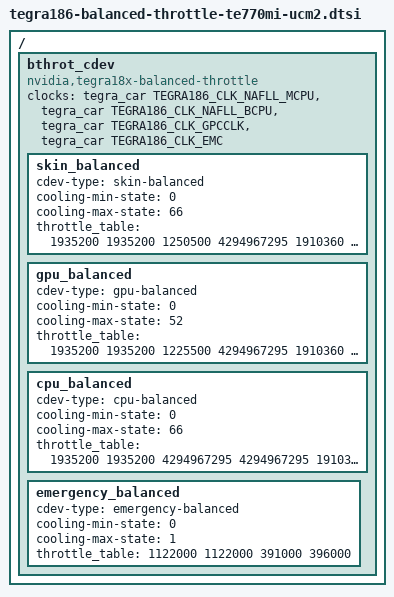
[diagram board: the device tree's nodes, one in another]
/*
 * arch/arm64/boot/dts/tegra186-platforms/tegra186-balanced-throttle-te770mi-ucm2.dtsi
 *
 * Copyright (c) 2015-2017, NVIDIA CORPORATION.  All rights reserved.
 *
 * This program is free software; you can redistribute it and/or modify
 * it under the terms of the GNU General Public License as published by
 * the Free Software Foundation; version 2 of the License.
 *
 * This program is distributed in the hope that it will be useful, but WITHOUT
 * ANY WARRANTY; without even the implied warranty of MERCHANTABILITY or
 * FITNESS FOR A PARTICULAR PURPOSE.  See the GNU General Public License for
 * more details.
 *
 * You should have received a copy of the GNU General Public License along
 * with this program; if not, write to the Free Software Foundation, Inc.,
 * 51 Franklin Street, Fifth Floor, Boston, MA  02110-1301, USA.
 *
 */

/{
	bthrot_cdev {
		compatible = "nvidia,tegra18x-balanced-throttle";
		clocks = <&tegra_car TEGRA186_CLK_NAFLL_MCPU>,
				 <&tegra_car TEGRA186_CLK_NAFLL_BCPU>,
				 <&tegra_car TEGRA186_CLK_GPCCLK>,
				 <&tegra_car TEGRA186_CLK_EMC>;
		clock-names = "mcpu", "bcpu", "gpu", "emc";

		skin_balanced {
			cdev-type = "skin-balanced";
			cooling-min-state = <0>;
			cooling-max-state = <66>;
			#cooling-cells = <2>;
			throttle_table = <
				1935200	1935200	1250500	4294967295
				1910360	1910360	1232796	4294967295
				1885520	1885520	1215092	4294967295
				1860680	1860680	1197388	4294967295
				1835840	1835840	1179685	4294967295
				1811000	1811000	1161981	4294967295
				1786160	1786160	1144277	4294967295
				1761320	1761320	1126573	4294967295
				1736480	1736480	1108869	4294967295
				1711640	1711640	1091165	4294967295
				1686800	1686800	1073462	4294967295
				1661960	1661960	1055758	4294967295
				1637120	1637120	1038054	4294967295
				1612280	1612280	1020350	4294967295
				1587440	1587440	1002646	4294967295
				1562600	1562600	984942	4294967295
				1537760	1537760	967238	4294967295
				1512920	1512920	949535	4294967295
				1488080	1488080	931831	4294967295
				1463240	1463240	914127	4294967295
				1438400	1438400	896423	4294967295
				1413560	1413560	878719	4294967295
				1388720	1388720	861015	4294967295
				1363880	1363880	843312	4294967295
				1339040	1339040	825608	4294967295
				1314200	1314200	807904	4294967295
				1289360	1289360	790200	4294967295
				1264520	1264520	772496	4294967295
				1239680	1239680	754792	4294967295
				1214840	1214840	737088	4294967295
				1190000	1190000	719385	4294967295
				1165160	1165160	701681	4294967295
				1140320	1140320	683977	4294967295
				1115480	1115480	666273	4294967295
				1090640	1090640	648569	4294967295
				1065800	1065800	630865	4294967295
				1040960	1040960	613162	4294967295
				1016120	1016120	595458	4294967295
				991280	991280	577754	4294967295
				966440	966440	560050	4294967295
				941600	941600	542346	4294967295
				916760	916760	524642	4294967295
				891920	891920	506938	4294967295
				867080	867080	489235	4294967295
				842240	842240	471531	4294967295
				817400	817400	453827	4294967295
				792560	792560	436123	4294967295
				767720	767720	418419	4294967295
				742880	742880	400715	4294967295
				718040	718040	383012	4294967295
				693200	693200	365308	4294967295
				668360	668360	347604	4294967295
				643520	643520	329900	4294967295
				618680	618680	312196	4294967295
				593840	593840	294492	4294967295
				569000	569000	276788	4294967295
				544160	544160	259085	4294967295
				519320	519320	241381	4294967295
				494480	494480	223677	4294967295
				469640	469640	205973	4294967295
				444800	444800	188269	4294967295
				419960	419960	170565	4294967295
				395120	395120	152862	4294967295
				370280	370280	135158	4294967295
				345440	345440	117454	4294967295
				320600	320600	99750	4294967295
			>;
		};
		gpu_balanced {
			cdev-type = "gpu-balanced";
			cooling-min-state = <0>;
			cooling-max-state = <52>;
			#cooling-cells = <2>;
			throttle_table = <
				1935200	1935200	1225500	4294967295
				1910360	1910360	1203426	4294967295
				1885520	1885520	1181353	4294967295
				1860680	1860680	1159279	4294967295
				1835840	1835840	1137206	4294967295
				1811000	1811000	1115132	4294967295
				1786160	1786160	1093059	4294967295
				1761320	1761320	1070985	4294967295
				1736480	1736480	1048912	4294967295
				1711640	1711640	1026838	4294967295
				1686800	1686800	1004765	4294967295
				1661960	1661960	982691	4294967295
				1637120	1637120	960618	4294967295
				1612280	1612280	938544	4294967295
				1587440	1587440	916471	4294967295
				1562600	1562600	894397	4294967295
				1537760	1537760	872324	4294967295
				1512920	1512920	850250	4294967295
				1488080	1488080	828176	4294967295
				1463240	1463240	806103	4294967295
				1438400	1438400	784029	4294967295
				1413560	1413560	761956	4294967295
				1388720	1388720	739882	4294967295
				1363880	1363880	717809	4294967295
				1339040	1339040	695735	4294967295
				1314200	1314200	673662	4294967295
				1289360	1289360	651588	4294967295
				1264520	1264520	629515	4294967295
				1239680	1239680	607441	4294967295
				1214840	1214840	585368	4294967295
				1190000	1190000	563294	4294967295
				1165160	1165160	541221	4294967295
				1140320	1140320	519147	4294967295
				1115480	1115480	497074	4294967295
				1090640	1090640	475000	4294967295
				1065800	1065800	452926	4294967295
				1040960	1040960	430853	4294967295
				1016120	1016120	408779	4294967295
				991280	991280	386706	4294967295
				966440	966440	364632	4294967295
				941600	941600	342559	4294967295
				916760	916760	320485	4294967295
				891920	891920	298412	4294967295
				867080	867080	276338	4294967295
				842240	842240	254265	4294967295
				817400	817400	232191	4294967295
				792560	792560	210118	4294967295
				767720	767720	188044	4294967295
				742880	742880	165971	4294967295
				718040	718040	143897	4294967295
				693200	693200	121824	4294967295
				668360	668360	99750	4294967295
			>;
		};
		cpu_balanced {
			cdev-type = "cpu-balanced";
			cooling-min-state = <0>;
			cooling-max-state = <66>;
			#cooling-cells = <2>;
			throttle_table = <
				1935200	1935200	4294967295	4294967295
				1910360	1910360	4294967295	4294967295
				1885520	1885520	4294967295	4294967295
				1860680	1860680	4294967295	4294967295
				1835840	1835840	4294967295	4294967295
				1811000	1811000	4294967295	4294967295
				1786160	1786160	4294967295	4294967295
				1761320	1761320	4294967295	4294967295
				1736480	1736480	4294967295	4294967295
				1711640	1711640	4294967295	4294967295
				1686800	1686800	1300500	4294967295
				1661960	1661960	1278668	4294967295
				1637120	1637120	1256836	4294967295
				1612280	1612280	1235005	4294967295
				1587440	1587440	1213173	4294967295
				1562600	1562600	1191341	4294967295
				1537760	1537760	1169509	4294967295
				1512920	1512920	1147677	4294967295
				1488080	1488080	1125845	4294967295
				1463240	1463240	1104014	4294967295
				1438400	1438400	1082182	4294967295
				1413560	1413560	1060350	4294967295
				1388720	1388720	1038518	4294967295
				1363880	1363880	1016686	4294967295
				1339040	1339040	994855	4294967295
				1314200	1314200	973023	4294967295
				1289360	1289360	951191	4294967295
				1264520	1264520	929359	4294967295
				1239680	1239680	907527	4294967295
				1214840	1214840	885695	4294967295
				1190000	1190000	863864	4294967295
				1165160	1165160	842032	4294967295
				1140320	1140320	820200	4294967295
				1115480	1115480	798368	4294967295
				1090640	1090640	776536	4294967295
				1065800	1065800	754705	4294967295
				1040960	1040960	732873	4294967295
				1016120	1016120	711041	4294967295
				991280	991280	689209	4294967295
				966440	966440	667377	4294967295
				941600	941600	645545	4294967295
				916760	916760	623714	4294967295
				891920	891920	601882	4294967295
				867080	867080	580050	4294967295
				842240	842240	558218	4294967295
				817400	817400	536386	4294967295
				792560	792560	514555	4294967295
				767720	767720	492723	4294967295
				742880	742880	470891	4294967295
				718040	718040	449059	4294967295
				693200	693200	427227	4294967295
				668360	668360	405395	4294967295
				643520	643520	383564	4294967295
				618680	618680	361732	4294967295
				593840	593840	339900	4294967295
				569000	569000	318068	4294967295
				544160	544160	296236	4294967295
				519320	519320	274405	4294967295
				494480	494480	252573	4294967295
				469640	469640	230741	4294967295
				444800	444800	208909	4294967295
				419960	419960	187077	4294967295
				395120	395120	165245	4294967295
				370280	370280	143414	4294967295
				345440	345440	121582	4294967295
				320600	320600	99750	4294967295
			>;
		};
		emergency_balanced {
			cdev-type = "emergency-balanced";
			cooling-min-state = <0>;
			cooling-max-state = <1>;
			#cooling-cells = <2>;
			throttle_table = <
				1122000	1122000	391000	396000
			>;
		};
	};
};
